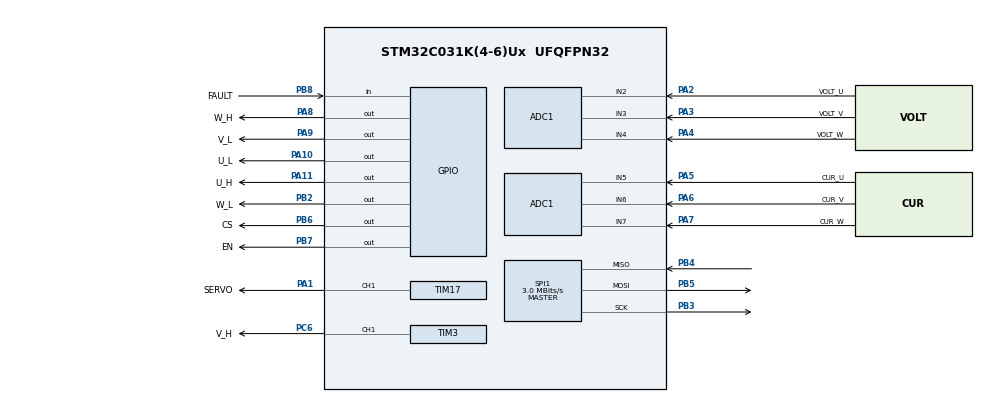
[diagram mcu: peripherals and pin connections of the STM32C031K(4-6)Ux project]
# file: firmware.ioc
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ADC1.Channel-0\#ChannelRegularConversion=ADC_CHANNEL_2
ADC1.Channel-1\#ChannelRegularConversion=ADC_CHANNEL_3
ADC1.Channel-2\#ChannelRegularConversion=ADC_CHANNEL_4
ADC1.ContinuousConvMode=DISABLE
ADC1.DiscontinuousConvMode=ENABLE
ADC1.EOCSelection=ADC_EOC_SINGLE_CONV
ADC1.EnableAnalogWatchDog1=true
ADC1.NbrOfConversion=3
ADC1.NbrOfConversionFlag=1
ADC1.Rank-0\#ChannelRegularConversion=1
ADC1.Rank-1\#ChannelRegularConversion=2
ADC1.Rank-2\#ChannelRegularConversion=3
ADC1.SamplingTime-0\#ChannelRegularConversion=ADC_SAMPLINGTIME_COMMON_1
ADC1.SamplingTime-1\#ChannelRegularConversion=ADC_SAMPLINGTIME_COMMON_1
ADC1.SamplingTime-2\#ChannelRegularConversion=ADC_SAMPLINGTIME_COMMON_1
ADC1.SelectedChannel=ADC_CHANNEL_2|ADC_CHANNEL_3|ADC_CHANNEL_4|ADC_CHANNEL_5|ADC_CHANNEL_6|ADC_CHANNEL_7
ADC1.master=1
Mcu.Family=STM32C0
Mcu.Name=STM32C031K(4-6)Ux
Mcu.Package=UFQFPN32
PA1.GPIO_Label=SERVO
PA1.Signal=S_TIM17_CH1
PA10.GPIO_Label=U_L
PA10.Signal=GPIO_Output
PA11\ [PA9].GPIO_Label=U_H
PA11\ [PA9].Signal=GPIO_Output
PA13.Mode=Serial_Wire
PA13.Signal=DEBUG_SWDIO
PA14-BOOT0.Mode=Serial_Wire
PA14-BOOT0.Signal=DEBUG_SWCLK
PA2.GPIO_Label=VOLT_U
PA2.Mode=IN2
PA2.Signal=ADC1_IN2
PA3.GPIO_Label=VOLT_V
PA3.Mode=IN3
PA3.Signal=ADC1_IN3
PA4.GPIO_Label=VOLT_W
PA4.Mode=IN4
PA4.Signal=ADC1_IN4
PA5.GPIO_Label=CUR_U
PA5.Mode=IN5
PA5.Signal=ADC1_IN5
PA6.GPIO_Label=CUR_V
PA6.Mode=IN6
PA6.Signal=ADC1_IN6
PA7.GPIO_Label=CUR_W
PA7.Mode=IN7
PA7.Signal=ADC1_IN7
PA8.GPIO_Label=W_H
PA8.Signal=GPIO_Output
PA9.GPIO_Label=V_L
PA9.Signal=GPIO_Output
PB2.GPIO_Label=W_L
PB2.Signal=GPIO_Output
PB3.Mode=Full_Duplex_Master
PB3.Signal=SPI1_SCK
PB4.Mode=Full_Duplex_Master
PB4.Signal=SPI1_MISO
PB5.Mode=Full_Duplex_Master
PB5.Signal=SPI1_MOSI
PB6.GPIO_Label=CS
PB6.Signal=GPIO_Output
PB7.GPIO_Label=EN
PB7.Signal=GPIO_Output
PB8.GPIO_Label=FAULT
PB8.Signal=GPIO_Input
PC14-OSCX_IN\ (PC14).Mode=HSE-External-Oscillator-REMAPPED
PC14-OSCX_IN\ (PC14).Signal=RCC_OSCX_IN
PC15-OSCX_OUT\ (PC15).Mode=HSE-External-Oscillator-REMAPPED
PC15-OSCX_OUT\ (PC15).Signal=RCC_OSCX_OUT
PC6.GPIO_Label=V_H
PC6.Signal=S_TIM3_CH1
ProjectManager.HeapSize=0x200
ProjectManager.StackSize=0x400
ProjectManager.TargetToolchain=Makefile
RCC.ADCFreq_Value=48000000
RCC.AHBFreq_Value=48000000
RCC.CortexFreq_Value=48000000
RCC.EXTERNAL_CLOCK_VALUE=12288000
RCC.HCLKFreq_Value=48000000
RCC.HSE_VALUE=8000000
RCC.HSISYSCLKDivider=RCC_HSI_DIV1
RCC.HSI_VALUE=48000000
RCC.LSE_VALUE=32768
RCC.SYSCLKFreq_VALUE=48000000
SH.S_TIM17_CH1.0=TIM17_CH1,PWM Generation1 CH1
SH.S_TIM3_CH1.0=TIM3_CH1,PWM Generation1 CH1
SPI1.BaudRatePrescaler=SPI_BAUDRATEPRESCALER_16
SPI1.CalculateBaudRate=3.0 MBits/s
SPI1.Direction=SPI_DIRECTION_2LINES
SPI1.Mode=SPI_MODE_MASTER
SPI1.VirtualType=VM_MASTER
TIM17.Channel=TIM_CHANNEL_1
TIM3.Channel-PWM\ Generation1\ CH1=TIM_CHANNEL_1
VP_TIM14_VS_ClockSourceINT.Mode=Enable_Timer
VP_TIM17_VS_ClockSourceINT.Mode=Enable_Timer
board=custom

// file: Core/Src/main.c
/* USER CODE BEGIN Header */
/**
  ******************************************************************************
  * @file           : main.c
  * @brief          : Main program body
  ******************************************************************************
  * @attention
  *
  * Copyright (c) 2024 STMicroelectronics.
  * All rights reserved.
  *
  * This software is licensed under terms that can be found in the LICENSE file
  * in the root directory of this software component.
  * If no LICENSE file comes with this software, it is provided AS-IS.
  *
  ******************************************************************************
  */
/* USER CODE END Header */
#include "main.h"
#include "adc.h"
#include "spi.h"
#include "tim.h"
#include "gpio.h"

/* USER CODE BEGIN Includes */
#include "esc_algorithm.h"
/* USER CODE END Includes */

/* USER CODE BEGIN PV */
ESC_stateMachine_t esc;
/* USER CODE END PV */

void SystemClock_Config(void);

int main(void)
{

  /* MCU Configuration--------------------------------------------------------*/

  /* Reset of all peripherals, Initializes the Flash interface and the Systick. */
  HAL_Init();

  /* Configure the system clock */
  SystemClock_Config();

  /* Initialize all configured peripherals */
  MX_GPIO_Init();
  MX_SPI1_Init();
  MX_ADC1_Init();
  MX_TIM3_Init();
  MX_TIM14_Init();
  MX_TIM17_Init();
  /* USER CODE BEGIN 2 */
  esc.hadc = &hadc1;
  ESC_init(&esc);
  /* USER CODE END 2 */

  /* Infinite loop */
  while (1)
  {

    /* USER CODE BEGIN 3 */
    ESC_measureVoltage(&esc);
    HAL_Delay(500);
  }
  /* USER CODE END 3 */
}

void SystemClock_Config(void)
{
  RCC_OscInitTypeDef RCC_OscInitStruct = {0};
  RCC_ClkInitTypeDef RCC_ClkInitStruct = {0};

  /** Initializes the RCC Oscillators according to the specified parameters
  * in the RCC_OscInitTypeDef structure.
  */
  RCC_OscInitStruct.OscillatorType = RCC_OSCILLATORTYPE_HSI;
  RCC_OscInitStruct.HSIState = RCC_HSI_ON;
  RCC_OscInitStruct.HSIDiv = RCC_HSI_DIV1;
  RCC_OscInitStruct.HSICalibrationValue = RCC_HSICALIBRATION_DEFAULT;
  if (HAL_RCC_OscConfig(&RCC_OscInitStruct) != HAL_OK)
  {
    Error_Handler();
  }

  /** Initializes the CPU, AHB and APB buses clocks
  */
  RCC_ClkInitStruct.ClockType = RCC_CLOCKTYPE_HCLK|RCC_CLOCKTYPE_SYSCLK
                              |RCC_CLOCKTYPE_PCLK1;
  RCC_ClkInitStruct.SYSCLKSource = RCC_SYSCLKSOURCE_HSI;
  RCC_ClkInitStruct.SYSCLKDivider = RCC_SYSCLK_DIV1;
  RCC_ClkInitStruct.AHBCLKDivider = RCC_HCLK_DIV1;
  RCC_ClkInitStruct.APB1CLKDivider = RCC_APB1_DIV1;

  if (HAL_RCC_ClockConfig(&RCC_ClkInitStruct, FLASH_LATENCY_1) != HAL_OK)
  {
    Error_Handler();
  }
}

void Error_Handler(void)
{
  __disable_irq();
  while (1)
  {
  }
}
